# Espressif register map
File version: 1.0
CPU: Xtensa LX6 1, little endian, no MPU, FPU, 3 interrupt priority bits
Registers are 32-bit, access not given, reset 0x0 unless marked. A register's access mark holds for its fields unless they carry their own. Offsets are from the block's base; [hi:lo] are bit positions.

## UART
Base 0x3FF40000
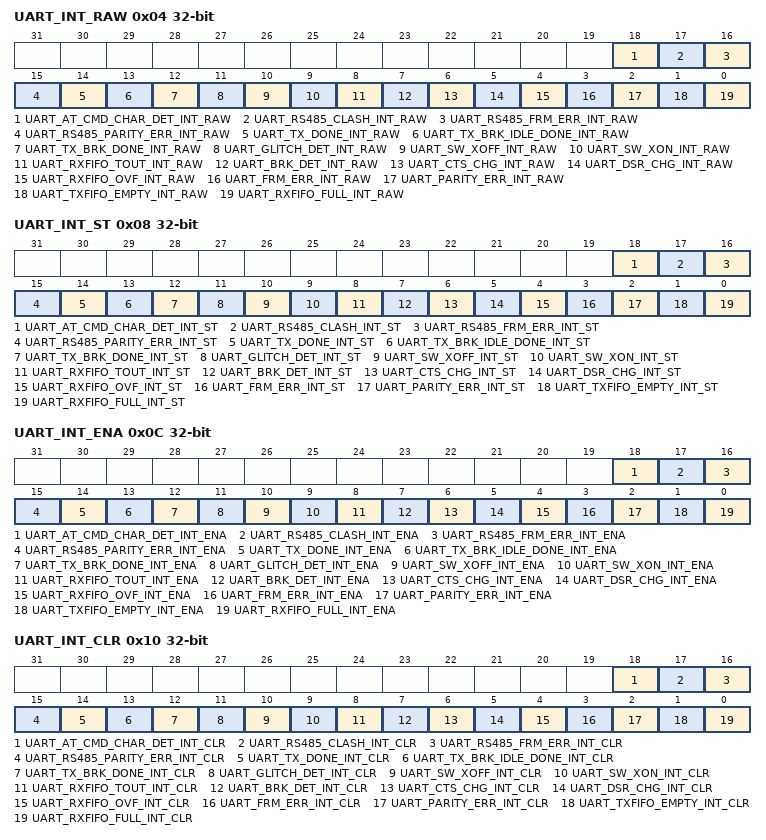
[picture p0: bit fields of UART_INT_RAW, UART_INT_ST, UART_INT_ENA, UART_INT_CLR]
0x04 UART_INT_RAW
  [18] UART_AT_CMD_CHAR_DET_INT_RAW, [17] UART_RS485_CLASH_INT_RAW, [16] UART_RS485_FRM_ERR_INT_RAW, [15] UART_RS485_PARITY_ERR_INT_RAW, [14] UART_TX_DONE_INT_RAW, [13] UART_TX_BRK_IDLE_DONE_INT_RAW, [12] UART_TX_BRK_DONE_INT_RAW, [11] UART_GLITCH_DET_INT_RAW, [10] UART_SW_XOFF_INT_RAW, [9] UART_SW_XON_INT_RAW, [8] UART_RXFIFO_TOUT_INT_RAW, [7] UART_BRK_DET_INT_RAW, [6] UART_CTS_CHG_INT_RAW, [5] UART_DSR_CHG_INT_RAW, [4] UART_RXFIFO_OVF_INT_RAW, [3] UART_FRM_ERR_INT_RAW, [2] UART_PARITY_ERR_INT_RAW, [1] UART_TXFIFO_EMPTY_INT_RAW, [0] UART_RXFIFO_FULL_INT_RAW
0x08 UART_INT_ST
  [18] UART_AT_CMD_CHAR_DET_INT_ST, [17] UART_RS485_CLASH_INT_ST, [16] UART_RS485_FRM_ERR_INT_ST, [15] UART_RS485_PARITY_ERR_INT_ST, [14] UART_TX_DONE_INT_ST, [13] UART_TX_BRK_IDLE_DONE_INT_ST, [12] UART_TX_BRK_DONE_INT_ST, [11] UART_GLITCH_DET_INT_ST, [10] UART_SW_XOFF_INT_ST, [9] UART_SW_XON_INT_ST, [8] UART_RXFIFO_TOUT_INT_ST, [7] UART_BRK_DET_INT_ST, [6] UART_CTS_CHG_INT_ST, [5] UART_DSR_CHG_INT_ST, [4] UART_RXFIFO_OVF_INT_ST, [3] UART_FRM_ERR_INT_ST, [2] UART_PARITY_ERR_INT_ST, [1] UART_TXFIFO_EMPTY_INT_ST, [0] UART_RXFIFO_FULL_INT_ST
0x0C UART_INT_ENA
  [18] UART_AT_CMD_CHAR_DET_INT_ENA, [17] UART_RS485_CLASH_INT_ENA, [16] UART_RS485_FRM_ERR_INT_ENA, [15] UART_RS485_PARITY_ERR_INT_ENA, [14] UART_TX_DONE_INT_ENA, [13] UART_TX_BRK_IDLE_DONE_INT_ENA, [12] UART_TX_BRK_DONE_INT_ENA, [11] UART_GLITCH_DET_INT_ENA, [10] UART_SW_XOFF_INT_ENA, [9] UART_SW_XON_INT_ENA, [8] UART_RXFIFO_TOUT_INT_ENA, [7] UART_BRK_DET_INT_ENA, [6] UART_CTS_CHG_INT_ENA, [5] UART_DSR_CHG_INT_ENA, [4] UART_RXFIFO_OVF_INT_ENA, [3] UART_FRM_ERR_INT_ENA, [2] UART_PARITY_ERR_INT_ENA, [1] UART_TXFIFO_EMPTY_INT_ENA, [0] UART_RXFIFO_FULL_INT_ENA
0x10 UART_INT_CLR
  [18] UART_AT_CMD_CHAR_DET_INT_CLR, [17] UART_RS485_CLASH_INT_CLR, [16] UART_RS485_FRM_ERR_INT_CLR, [15] UART_RS485_PARITY_ERR_INT_CLR, [14] UART_TX_DONE_INT_CLR, [13] UART_TX_BRK_IDLE_DONE_INT_CLR, [12] UART_TX_BRK_DONE_INT_CLR, [11] UART_GLITCH_DET_INT_CLR, [10] UART_SW_XOFF_INT_CLR, [9] UART_SW_XON_INT_CLR, [8] UART_RXFIFO_TOUT_INT_CLR, [7] UART_BRK_DET_INT_CLR, [6] UART_CTS_CHG_INT_CLR, [5] UART_DSR_CHG_INT_CLR, [4] UART_RXFIFO_OVF_INT_CLR, [3] UART_FRM_ERR_INT_CLR, [2] UART_PARITY_ERR_INT_CLR, [1] UART_TXFIFO_EMPTY_INT_CLR, [0] UART_RXFIFO_FULL_INT_CLR
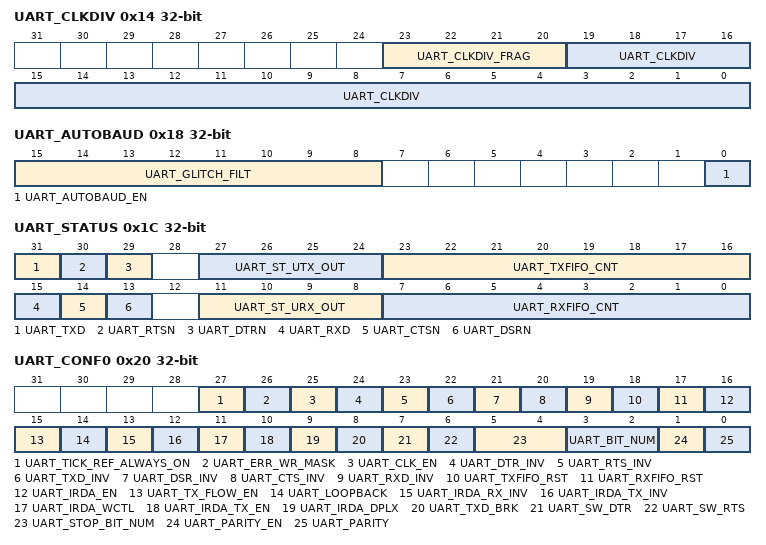
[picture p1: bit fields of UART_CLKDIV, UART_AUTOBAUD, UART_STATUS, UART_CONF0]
0x14 UART_CLKDIV
  [23:20] UART_CLKDIV_FRAG, [19:0] UART_CLKDIV
0x18 UART_AUTOBAUD
  [15:8] UART_GLITCH_FILT, [0] UART_AUTOBAUD_EN
0x1C UART_STATUS
  [31] UART_TXD, [30] UART_RTSN, [29] UART_DTRN, [27:24] UART_ST_UTX_OUT, [23:16] UART_TXFIFO_CNT, [15] UART_RXD, [14] UART_CTSN, [13] UART_DSRN, [11:8] UART_ST_URX_OUT, [7:0] UART_RXFIFO_CNT
0x20 UART_CONF0
  [27] UART_TICK_REF_ALWAYS_ON, [26] UART_ERR_WR_MASK, [25] UART_CLK_EN, [24] UART_DTR_INV, [23] UART_RTS_INV, [22] UART_TXD_INV, [21] UART_DSR_INV, [20] UART_CTS_INV, [19] UART_RXD_INV, [18] UART_TXFIFO_RST, [17] UART_RXFIFO_RST, [16] UART_IRDA_EN, [15] UART_TX_FLOW_EN, [14] UART_LOOPBACK, [13] UART_IRDA_RX_INV, [12] UART_IRDA_TX_INV, [11] UART_IRDA_WCTL, [10] UART_IRDA_TX_EN, [9] UART_IRDA_DPLX, [8] UART_TXD_BRK, [7] UART_SW_DTR, [6] UART_SW_RTS, [5:4] UART_STOP_BIT_NUM, [3:2] UART_BIT_NUM, [1] UART_PARITY_EN, [0] UART_PARITY
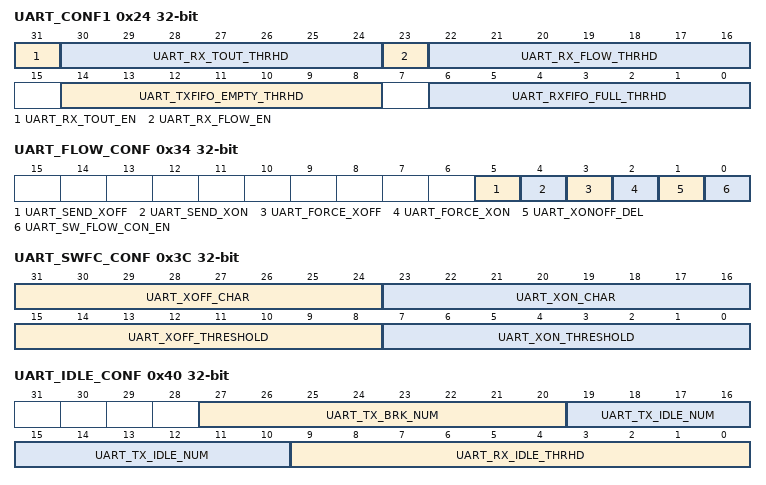
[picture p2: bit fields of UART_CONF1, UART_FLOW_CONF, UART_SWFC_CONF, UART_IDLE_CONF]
0x24 UART_CONF1
  [31] UART_RX_TOUT_EN, [30:24] UART_RX_TOUT_THRHD, [23] UART_RX_FLOW_EN, [22:16] UART_RX_FLOW_THRHD, [14:8] UART_TXFIFO_EMPTY_THRHD, [6:0] UART_RXFIFO_FULL_THRHD
0x28 UART_LOWPULSE
  [19:0] UART_LOWPULSE_MIN_CNT
0x2C UART_HIGHPULSE
  [19:0] UART_HIGHPULSE_MIN_CNT
0x30 UART_RXD_CNT
  [9:0] UART_RXD_EDGE_CNT
0x34 UART_FLOW_CONF
  [5] UART_SEND_XOFF, [4] UART_SEND_XON, [3] UART_FORCE_XOFF, [2] UART_FORCE_XON, [1] UART_XONOFF_DEL, [0] UART_SW_FLOW_CON_EN
0x38 UART_SLEEP_CONF
  [9:0] UART_ACTIVE_THRESHOLD
0x3C UART_SWFC_CONF
  [31:24] UART_XOFF_CHAR, [23:16] UART_XON_CHAR, [15:8] UART_XOFF_THRESHOLD, [7:0] UART_XON_THRESHOLD
0x40 UART_IDLE_CONF
  [27:20] UART_TX_BRK_NUM, [19:10] UART_TX_IDLE_NUM, [9:0] UART_RX_IDLE_THRHD
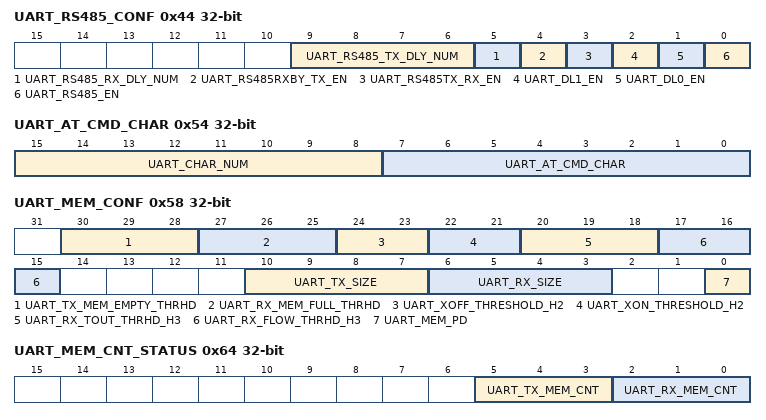
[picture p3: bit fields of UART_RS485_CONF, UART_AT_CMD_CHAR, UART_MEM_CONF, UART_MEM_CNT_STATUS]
0x44 UART_RS485_CONF
  [9:6] UART_RS485_TX_DLY_NUM, [5] UART_RS485_RX_DLY_NUM, [4] UART_RS485RXBY_TX_EN, [3] UART_RS485TX_RX_EN, [2] UART_DL1_EN, [1] UART_DL0_EN, [0] UART_RS485_EN
0x48 UART_AT_CMD_PRECNT
  [23:0] UART_PRE_IDLE_NUM
0x4C UART_AT_CMD_POSTCNT
  [23:0] UART_POST_IDLE_NUM
0x50 UART_AT_CMD_GAPTOUT
  [23:0] UART_RX_GAP_TOUT
0x54 UART_AT_CMD_CHAR
  [15:8] UART_CHAR_NUM, [7:0] UART_AT_CMD_CHAR
0x58 UART_MEM_CONF
  [30:28] UART_TX_MEM_EMPTY_THRHD, [27:25] UART_RX_MEM_FULL_THRHD, [24:23] UART_XOFF_THRESHOLD_H2, [22:21] UART_XON_THRESHOLD_H2, [20:18] UART_RX_TOUT_THRHD_H3, [17:15] UART_RX_FLOW_THRHD_H3, [10:7] UART_TX_SIZE, [6:3] UART_RX_SIZE, [0] UART_MEM_PD
0x5C UART_MEM_TX_STATUS
  [23:0] UART_MEM_TX_STATUS
0x60 UART_MEM_RX_STATUS
  [23:13] UART_MEM_RX_WR_ADDR, [12:2] UART_MEM_RX_RD_ADDR, [23:0] UART_MEM_RX_STATUS
0x64 UART_MEM_CNT_STATUS
  [5:3] UART_TX_MEM_CNT, [2:0] UART_RX_MEM_CNT
0x68 UART_POSPULSE
  [19:0] UART_POSEDGE_MIN_CNT
0x6C UART_NEGPULSE
  [19:0] UART_NEGEDGE_MIN_CNT
0x78 UART_DATE
0x7C UART_ID
